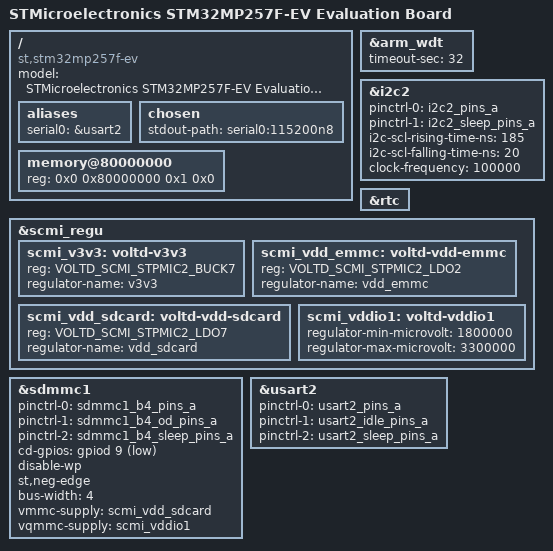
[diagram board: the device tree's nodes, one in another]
// SPDX-License-Identifier: (GPL-2.0-or-later OR BSD-3-Clause)
/*
 * Copyright (C) STMicroelectronics 2023 - All Rights Reserved
 * Author: Alexandre Torgue <alexandre.torgue@foss.st.com> for STMicroelectronics.
 */

/dts-v1/;

#include <dt-bindings/gpio/gpio.h>
#include <dt-bindings/regulator/st,stm32mp25-regulator.h>
#include "stm32mp257.dtsi"
#include "stm32mp25xf.dtsi"
#include "stm32mp25-pinctrl.dtsi"
#include "stm32mp25xxai-pinctrl.dtsi"
#include "stm32mp257f-ev-ca35tdcid-resmem.dtsi"

/ {
	model = "STMicroelectronics STM32MP257F-EV Evaluation Board";
	compatible = "st,stm32mp257f-ev", "st,stm32mp257";

	aliases {
		serial0 = &usart2;
	};

	chosen {
		stdout-path = "serial0:115200n8";
	};

	memory@80000000 {
		device_type = "memory";
		reg = <0x0 0x80000000 0x1 0x0>;
	};
};

&arm_wdt {
	timeout-sec = <32>;
	status = "okay";
};

&i2c2 {
	pinctrl-names = "default", "sleep";
	pinctrl-0 = <&i2c2_pins_a>;
	pinctrl-1 = <&i2c2_sleep_pins_a>;
	i2c-scl-rising-time-ns = <185>;
	i2c-scl-falling-time-ns = <20>;
	clock-frequency = <100000>;
	status = "okay";
	/* spare dmas for other usage */
	/delete-property/dmas;
	/delete-property/dma-names;
};

&rtc {
	status = "okay";
};

&scmi_regu {
	scmi_v3v3: voltd-v3v3 {
		reg = <VOLTD_SCMI_STPMIC2_BUCK7>;
		regulator-name = "v3v3";
	};
	scmi_vdd_emmc: voltd-vdd-emmc {
		reg = <VOLTD_SCMI_STPMIC2_LDO2>;
		regulator-name = "vdd_emmc";
	};
	scmi_vdd_sdcard: voltd-vdd-sdcard {
		reg = <VOLTD_SCMI_STPMIC2_LDO7>;
		regulator-name = "vdd_sdcard";
	};
	scmi_vddio1: voltd-vddio1 {
		regulator-min-microvolt = <1800000>;
		regulator-max-microvolt = <3300000>;
	};
};

&sdmmc1 {
	pinctrl-names = "default", "opendrain", "sleep";
	pinctrl-0 = <&sdmmc1_b4_pins_a>;
	pinctrl-1 = <&sdmmc1_b4_od_pins_a>;
	pinctrl-2 = <&sdmmc1_b4_sleep_pins_a>;
	cd-gpios = <&gpiod 9 (GPIO_ACTIVE_LOW | GPIO_PULL_UP)>;
	disable-wp;
	st,neg-edge;
	bus-width = <4>;
	vmmc-supply = <&scmi_vdd_sdcard>;
	vqmmc-supply = <&scmi_vddio1>;
	status = "okay";
};

&usart2 {
	pinctrl-names = "default", "idle", "sleep";
	pinctrl-0 = <&usart2_pins_a>;
	pinctrl-1 = <&usart2_idle_pins_a>;
	pinctrl-2 = <&usart2_sleep_pins_a>;
	/delete-property/dmas;
	/delete-property/dma-names;
	status = "okay";
};
